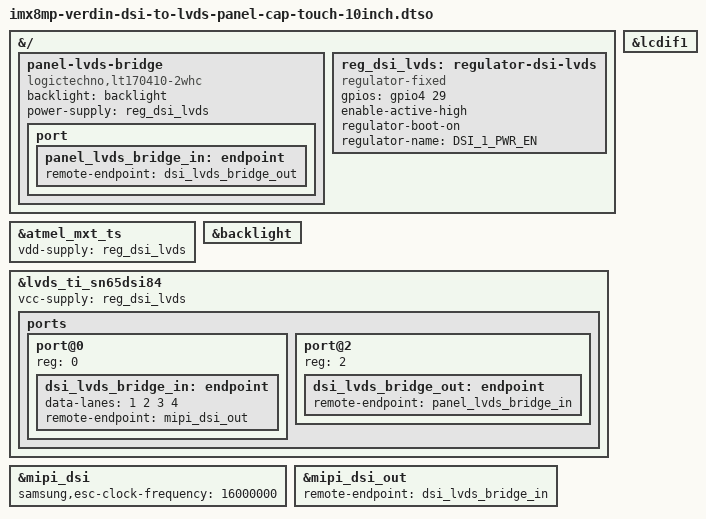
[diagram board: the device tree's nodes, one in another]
// SPDX-License-Identifier: GPL-2.0-or-later OR MIT
/*
 * Copyright (c) Toradex
 *
 * Toradex DSI to LVDS Adapter on Verdin DSI_1 with Capacitive Touch Display
 * 10.1", used on Dahlia (X17) and Development Board (X48) that expose DSI_1
 * via a Samtec LSS-130 connector.
 *
 * https://developer.toradex.com/hardware/accessories/displays/capacitive-touch-display-101inch-lvds
 * https://www.toradex.com/accessories/capacitive-touch-display-10.1-inch-lvds
 * https://developer.toradex.com/hardware/accessories/add-ons/dsi-lvds-adapter
 * https://www.toradex.com/accessories/verdin-dsi-to-lvds-adapter
 */

/dts-v1/;
/plugin/;

#include <dt-bindings/gpio/gpio.h>
#include <dt-bindings/interrupt-controller/irq.h>

&{/} {
	panel-lvds-bridge {
		compatible = "logictechno,lt170410-2whc";
		backlight = <&backlight>;
		power-supply = <&reg_dsi_lvds>;

		port {
			panel_lvds_bridge_in: endpoint {
				remote-endpoint = <&dsi_lvds_bridge_out>;
			};
		};
	};

	reg_dsi_lvds: regulator-dsi-lvds {
		compatible = "regulator-fixed";
		/* Verdin CTRL_SLEEP_MOCI# (SODIMM 256) */
		gpios = <&gpio4 29 GPIO_ACTIVE_HIGH>;
		enable-active-high;
		regulator-boot-on;
		regulator-name = "DSI_1_PWR_EN";
	};
};

&atmel_mxt_ts {
	vdd-supply = <&reg_dsi_lvds>;

	status = "okay";
};

&backlight {
	status = "okay";
};

&lcdif1 {
	status = "okay";
};

&lvds_ti_sn65dsi84 {
	vcc-supply = <&reg_dsi_lvds>;

	status = "okay";

	ports {
		#address-cells = <1>;
		#size-cells = <0>;

		port@0 {
			reg = <0>;

			dsi_lvds_bridge_in: endpoint {
				data-lanes = <1 2 3 4>;
				remote-endpoint = <&mipi_dsi_out>;
			};
		};

		port@2 {
			reg = <2>;

			dsi_lvds_bridge_out: endpoint {
				remote-endpoint = <&panel_lvds_bridge_in>;
			};
		};
	};
};

&mipi_dsi {
	samsung,esc-clock-frequency = <16000000>;

	status = "okay";
};

&mipi_dsi_out {
	remote-endpoint = <&dsi_lvds_bridge_in>;
};
